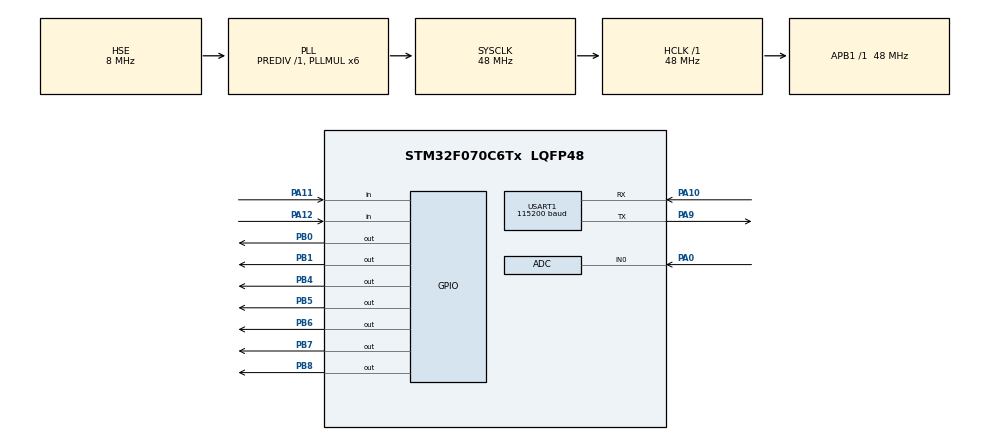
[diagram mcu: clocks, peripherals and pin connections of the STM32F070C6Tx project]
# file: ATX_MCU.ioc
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ADC.DiscontinuousConvMode=ENABLE
ADC.SamplingTime=ADC_SAMPLETIME_1CYCLE_5
Mcu.Family=STM32F0
Mcu.Name=STM32F070C6Tx
Mcu.Package=LQFP48
NVIC.USART1_IRQn=true\:0\:0\:false\:false\:true\:true\:true
PA0.Mode=IN0
PA0.Signal=ADC_IN0
PA1.Signal=ADC_IN1
PA10.Mode=Asynchronous
PA10.Signal=USART1_RX
PA11.GPIO_Mode=GPIO_MODE_INPUT
PA11.GPIO_PuPd=GPIO_NOPULL
PA11.Signal=GPIO_Input
PA12.GPIO_Mode=GPIO_MODE_INPUT
PA12.GPIO_PuPd=GPIO_NOPULL
PA12.Signal=GPIO_Input
PA13.Mode=Serial_Wire
PA13.Signal=SYS_SWDIO
PA14.Mode=Serial_Wire
PA14.Signal=SYS_SWCLK
PA2.Signal=ADC_IN2
PA3.Signal=ADC_IN3
PA4.Signal=ADC_IN4
PA5.Signal=ADC_IN5
PA6.Signal=ADC_IN6
PA7.Signal=ADC_IN7
PA9.Mode=Asynchronous
PA9.Signal=USART1_TX
PB0.Signal=GPIO_Output
PB1.Signal=GPIO_Output
PB4.Signal=GPIO_Output
PB5.Signal=GPIO_Output
PB6.Signal=GPIO_Output
PB7.Signal=GPIO_Output
PB8.Signal=GPIO_Output
PF0-OSC_IN.Mode=HSE-External-Oscillator
PF0-OSC_IN.Signal=RCC_OSC_IN
PF1-OSC_OUT.Mode=HSE-External-Oscillator
PF1-OSC_OUT.Signal=RCC_OSC_OUT
ProjectManager.HeapSize=0x200
ProjectManager.StackSize=0x400
ProjectManager.TargetToolchain=Makefile
RCC.AHBFreq_Value=48000000
RCC.APB1Freq_Value=48000000
RCC.APB1TimFreq_Value=48000000
RCC.HCLKFreq_Value=48000000
RCC.PLLMUL=RCC_PLL_MUL6
RCC.PLLSourceVirtual=RCC_PLLSOURCE_HSE
RCC.SYSCLKFreq_VALUE=48000000
RCC.SYSCLKSource=RCC_SYSCLKSOURCE_PLLCLK
USART1.BaudRate=115200
USART1.VirtualMode-Asynchronous=VM_ASYNC
board=custom

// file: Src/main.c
/* USER CODE BEGIN Header */
/**
  ******************************************************************************
  * @file           : main.c
  * @brief          : Main program body
  ******************************************************************************
  * @attention
  *
  * <h2><center>&copy; Copyright (c) 2020 STMicroelectronics.
  * All rights reserved.</center></h2>
  *
  * This software component is licensed by ST under BSD 3-Clause license,
  * the "License"; You may not use this file except in compliance with the
  * License. You may obtain a copy of the License at:
  *                        opensource.org/licenses/BSD-3-Clause
  *
  ******************************************************************************
  */
/* USER CODE END Header */
#include "main.h"
#include "adc.h"
#include "usart.h"
#include "gpio.h"

/* USER CODE BEGIN Includes */
#include "UART.h"

/* USER CODE END Includes */

void SystemClock_Config(void);

/* USER CODE BEGIN 0 */
uint32_t adc_vals[2];
/* USER CODE END 0 */

int main(void)
{

  /* MCU Configuration--------------------------------------------------------*/

  /* Reset of all peripherals, Initializes the Flash interface and the Systick. */
  HAL_Init();

  /* Configure the system clock */
  SystemClock_Config();

  /* Initialize all configured peripherals */
  MX_GPIO_Init();
  MX_ADC_Init();
  MX_USART1_UART_Init();
  /* USER CODE BEGIN 2 */

  UART_send_str(&huart1, "System boot\r\n");
  HAL_ADC_Start_DMA(&hadc, adc_vals, 2);

  /* USER CODE END 2 */

  /* Infinite loop */
  /* USER CODE BEGIN WHILE */
  while (1)
  {
    HAL_GPIO_WritePin(GPIOB, GPIO_PIN_8, GPIO_PIN_SET);
    HAL_Delay(1U);
    HAL_GPIO_WritePin(GPIOB, GPIO_PIN_8, GPIO_PIN_RESET);

    HAL_Delay(999U);

    //HAL_ADC_Start(&hadc);
    //HAL_ADC_PollForConversion(&hadc, 1);
    //val_ADC1 = HAL_ADC_GetValue(&hadc)/(0xFFFF)*3.3f;
    //UART_send_int(&huart1, (uint16_t)val_ADC1);

    /* USER CODE END WHILE */

  }
}

void SystemClock_Config(void)
{
  RCC_OscInitTypeDef RCC_OscInitStruct = {0};
  RCC_ClkInitTypeDef RCC_ClkInitStruct = {0};
  RCC_PeriphCLKInitTypeDef PeriphClkInit = {0};

  /** Initializes the RCC Oscillators according to the specified parameters
  * in the RCC_OscInitTypeDef structure.
  */
  RCC_OscInitStruct.OscillatorType = RCC_OSCILLATORTYPE_HSI14|RCC_OSCILLATORTYPE_HSE;
  RCC_OscInitStruct.HSEState = RCC_HSE_ON;
  RCC_OscInitStruct.HSI14State = RCC_HSI14_ON;
  RCC_OscInitStruct.HSI14CalibrationValue = 16;
  RCC_OscInitStruct.PLL.PLLState = RCC_PLL_ON;
  RCC_OscInitStruct.PLL.PLLSource = RCC_PLLSOURCE_HSE;
  RCC_OscInitStruct.PLL.PLLMUL = RCC_PLL_MUL6;
  RCC_OscInitStruct.PLL.PREDIV = RCC_PREDIV_DIV1;
  if (HAL_RCC_OscConfig(&RCC_OscInitStruct) != HAL_OK)
  {
    Error_Handler();
  }
  /** Initializes the CPU, AHB and APB buses clocks
  */
  RCC_ClkInitStruct.ClockType = RCC_CLOCKTYPE_HCLK|RCC_CLOCKTYPE_SYSCLK
                              |RCC_CLOCKTYPE_PCLK1;
  RCC_ClkInitStruct.SYSCLKSource = RCC_SYSCLKSOURCE_PLLCLK;
  RCC_ClkInitStruct.AHBCLKDivider = RCC_SYSCLK_DIV1;
  RCC_ClkInitStruct.APB1CLKDivider = RCC_HCLK_DIV1;

  if (HAL_RCC_ClockConfig(&RCC_ClkInitStruct, FLASH_LATENCY_1) != HAL_OK)
  {
    Error_Handler();
  }
  PeriphClkInit.PeriphClockSelection = RCC_PERIPHCLK_USART1;
  PeriphClkInit.Usart1ClockSelection = RCC_USART1CLKSOURCE_PCLK1;
  if (HAL_RCCEx_PeriphCLKConfig(&PeriphClkInit) != HAL_OK)
  {
    Error_Handler();
  }
}

void Error_Handler(void)
{
}

/************************ (C) COPYRIGHT STMicroelectronics *****END OF FILE****/
